# ATmega64A device description
Architecture: AVR8; Family: megaAVR
Registers are 8-bit, access not given, no defined reset value unless marked. A register's access mark holds for its fields unless they carry their own. Offsets are from the block's base; [hi:lo] are bit positions.

## LOCKBIT — Lockbits
Instances: LOCKBIT 0 in lockbits
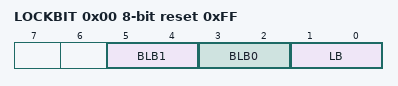
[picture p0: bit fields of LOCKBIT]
0x00 LOCKBIT reset 0xFF
  [5:4] BLB1 — Boot Loader Protection Mode
    0=LPM_SPM_DISABLE (LPM and SPM prohibited in Boot Section); 1=LPM_DISABLE (LPM prohibited in Boot Section); 2=SPM_DISABLE (SPM prohibited in Boot Section); 3=NO_LOCK (No lock on SPM and LPM in Boot Section)
  [3:2] BLB0 — Boot Loader Protection Mode
    0=LPM_SPM_DISABLE (LPM and SPM prohibited in Application Section); 1=LPM_DISABLE (LPM prohibited in Application Section); 2=SPM_DISABLE (SPM prohibited in Application Section); 3=NO_LOCK (No lock on SPM and LPM in Application Section)
  [1:0] LB — Memory Lock
    0=PROG_VER_DISABLED (Further programming and verification disabled); 2=PROG_DISABLED (Further programming disabled); 3=NO_LOCK (No memory lock features enabled)

## AC — Analog Comparator
Instances: AC 0x00
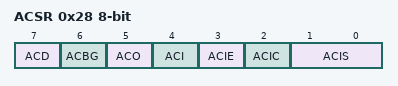
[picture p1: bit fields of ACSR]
0x28 ACSR — Analog Comparator Control And Status Register
  [7] ACD — Analog Comparator Disable
  [6] ACBG — Analog Comparator Bandgap Select
  [5] ACO — Analog Compare Output
  [4] ACI — Analog Comparator Interrupt Flag
  [3] ACIE — Analog Comparator Interrupt Enable
  [2] ACIC — Analog Comparator Input Capture Enable
  [1:0] ACIS — Analog Comparator Interrupt Mode Select bits
    0=Interrupt on Toggle; 2=Interrupt on Falling Edge; 3=Interrupt on Rising Edge
0x40 SFIOR — Special Function IO Register
  [3] ACME — Analog Comparator Multiplexer Enable

## ADC — Analog-to-Digital Converter
Instances: ADC 0x00
0x24 ADC 16-bit — ADC Data Register Bytes
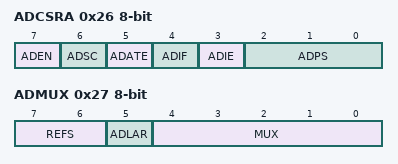
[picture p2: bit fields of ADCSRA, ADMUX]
0x26 ADCSRA — The ADC Control and Status register A
  [7] ADEN — ADC Enable
  [6] ADSC — ADC Start Conversion
  [5] ADATE — ADC Auto Trigger Enable
  [4] ADIF — ADC Interrupt Flag
  [3] ADIE — ADC Interrupt Enable
  [2:0] ADPS — ADC Prescaler Select Bits
    0=2; 1=2; 2=4; 3=8; 4=16; 5=32; 6=64; 7=128
0x27 ADMUX — The ADC multiplexer Selection Register
  [7:6] REFS — Reference Selection Bits
    0=AREF, Internal Vref turned off; 1=AVCC with external capacitor at AREF pin; 3=Internal 2.56V Voltage Reference with external capacitor at AREF pin
  [5] ADLAR — Left Adjust Result
  [4:0] MUX — Analog Channel and Gain Selection Bits
0x8E ADCSRB — The ADC Control and Status register B
  [2:0] ADTS — ADC Auto Trigger Source bits
    0=Free Running mode; 1=Analog Comparator; 2=External Interrupt Request 0; 3=Timer/Counter0 Compare Match A; 4=Timer/Counter0 Overflow; 5=Timer/Counter1 Compare Match B; 6=Timer/Counter1 Overflow; 7=Timer/Counter1 Capture Event

## SPI — Serial Peripheral Interface
Instances: SPI 0x00
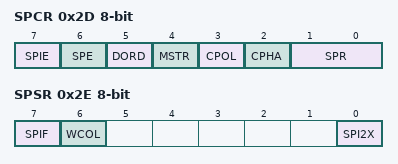
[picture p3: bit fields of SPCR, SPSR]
0x2D SPCR — SPI Control Register
  [7] SPIE — SPI Interrupt Enable
  [6] SPE — SPI Enable
  [5] DORD — Data Order
  [4] MSTR — Master/Slave Select
  [3] CPOL — Clock polarity
  [2] CPHA — Clock Phase
  [1:0] SPR — SPI Clock Rate Selects
    0=fosc/4; 1=fosc/16; 2=fosc/64; 3=fosc/128; 4=fosc/2; 5=fosc/8; 6=fosc/32; 7=fosc/64
0x2E SPSR — SPI Status Register
  [7] SPIF — SPI Interrupt Flag
  [6] WCOL — Write Collision Flag
  [0] SPI2X — Double SPI Speed Bit
0x2F SPDR — SPI Data Register

## TWI — Two Wire Serial Interface
Instances: TWI 0x00
0x70 TWBR — TWI Bit Rate register
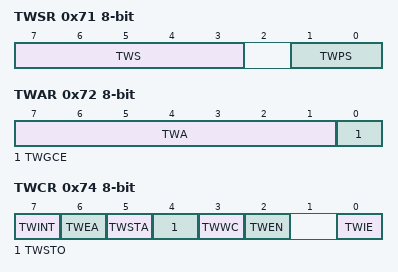
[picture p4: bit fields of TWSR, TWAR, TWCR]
0x71 TWSR — TWI Status Register
  [7:3] TWS (bit 3 of the value upward) — TWI Status
  [1:0] TWPS — TWI Prescaler
    0=1; 1=4; 2=16; 3=64
0x72 TWAR — TWI (Slave) Address register
  [7:1] TWA — TWI (Slave) Address register Bits
  [0] TWGCE — TWI General Call Recognition Enable Bit
0x73 TWDR — TWI Data register
0x74 TWCR — TWI Control Register
  [7] TWINT — TWI Interrupt Flag
  [6] TWEA — TWI Enable Acknowledge Bit
  [5] TWSTA — TWI Start Condition Bit
  [4] TWSTO — TWI Stop Condition Bit
  [3] TWWC — TWI Write Collition Flag
  [2] TWEN — TWI Enable Bit
  [0] TWIE — TWI Interrupt Enable
